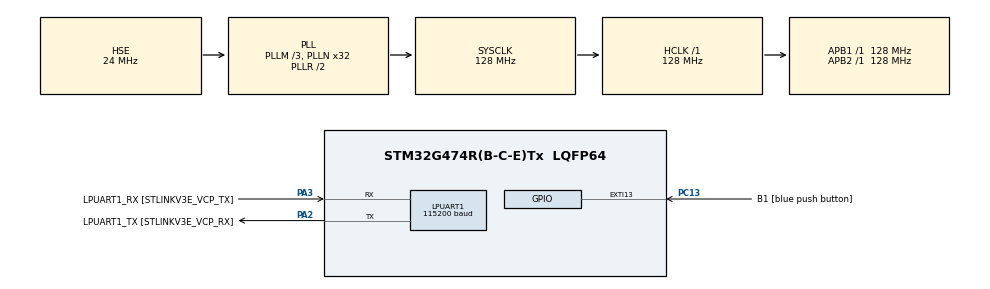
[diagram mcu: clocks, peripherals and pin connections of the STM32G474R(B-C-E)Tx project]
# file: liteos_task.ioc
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LPUART1.BaudRate=115200
LPUART1.WordLength=UART_WORDLENGTH_8B
Mcu.Family=STM32G4
Mcu.Name=STM32G474R(B-C-E)Tx
Mcu.Package=LQFP64
NVIC.EXTI15_10_IRQn=true\:0\:0\:false\:false\:true\:true\:true
NVIC.PriorityGroup=NVIC_PRIORITYGROUP_4
NVIC.TIM4_IRQn=true\:15\:0\:false\:false\:true\:false\:true
NVIC.TimeBase=TIM4_IRQn
NVIC.TimeBaseIP=TIM4
PA13.GPIO_Label=T_SWDIO
PA13.Mode=Serial_Wire
PA13.Signal=SYS_JTMS-SWDIO
PA14.GPIO_Label=T_SWCLK
PA14.Mode=Serial_Wire
PA14.Signal=SYS_JTCK-SWCLK
PA2.GPIO_Label=LPUART1_TX [STLINKV3E_VCP_RX]
PA2.Mode=Asynchronous
PA2.Signal=LPUART1_TX
PA3.GPIO_Label=LPUART1_RX [STLINKV3E_VCP_TX]
PA3.Mode=Asynchronous
PA3.Signal=LPUART1_RX
PA5.GPIO_Label=M_SPI1_SCK
PA5.GPIO_PuPd=GPIO_PULLUP
PA5.GPIO_Speed=GPIO_SPEED_FREQ_HIGH
PA5.Signal=SPI1_SCK
PB3.GPIO_Label=T_SWO
PB3.Signal=SYS_JTDO-SWO
PC13.GPIO_Label=B1 [blue push button]
PC13.Signal=GPXTI13
PC14-OSC32_IN.Signal=RCC_OSC32_IN
PC15-OSC32_OUT.Signal=RCC_OSC32_OUT
PF0-OSC_IN.Mode=HSE-External-Oscillator
PF0-OSC_IN.Signal=RCC_OSC_IN
PF1-OSC_OUT.Mode=HSE-External-Oscillator
PF1-OSC_OUT.Signal=RCC_OSC_OUT
ProjectManager.HeapSize=0x200
ProjectManager.StackSize=0x400
ProjectManager.TargetToolchain=STM32CubeIDE
RCC.ADC12Freq_Value=128000000
RCC.ADC345Freq_Value=128000000
RCC.AHBFreq_Value=128000000
RCC.APB1Freq_Value=128000000
RCC.APB1TimFreq_Value=128000000
RCC.APB2Freq_Value=128000000
RCC.APB2TimFreq_Value=128000000
RCC.CortexFreq_Value=128000000
RCC.EXTERNAL_CLOCK_VALUE=12288000
RCC.HCLKFreq_Value=128000000
RCC.HSE_VALUE=24000000
RCC.HSI48_VALUE=48000000
RCC.HSI_VALUE=16000000
RCC.PLLM=RCC_PLLM_DIV3
RCC.PLLN=32
RCC.PLLSourceVirtual=RCC_PLLSOURCE_HSE
RCC.RTCClockSelection=RCC_RTCCLKSOURCE_LSE
RCC.SYSCLKFreq_VALUE=128000000
RCC.SYSCLKSource=RCC_SYSCLKSOURCE_PLLCLK
RCC.USBFreq_Value=128000000
RCC.VCOOutputFreq_Value=256000000
VP_SYS_VS_DBSignals.Mode=DisableDeadBatterySignals
VP_SYS_VS_tim4.Mode=TIM4
board=NUCLEO-G474RE

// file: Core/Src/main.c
/* USER CODE BEGIN Header */
/**
 ******************************************************************************
 * @file           : main.c
 * @brief          : Main program body
 ******************************************************************************
 * @attention
 *
 * <h2><center>&copy; Copyright (c) 2021 STMicroelectronics.
 * All rights reserved.</center></h2>
 *
 * This software component is licensed by ST under BSD 3-Clause license,
 * the "License"; You may not use this file except in compliance with the
 * License. You may obtain a copy of the License at:
 *                        opensource.org/licenses/BSD-3-Clause
 *
 ******************************************************************************
 */
/* USER CODE END Header */
#include "main.h"
#include "usart.h"
#include "gpio.h"

/* USER CODE BEGIN Includes */
#include "stdio.h"
#include "task1.h"
#include "task2.h"

/* USER CODE END Includes */

/* USER CODE BEGIN PV */

//task1
/**/
UINT32 led1_task_handle;
UINT32 led2_task_handle;
UINT32 print_task_handle;

//task2
/**/
osThreadId_t LED0TaskHandle;
const osThreadAttr_t LED0Task_attributes = {
  .name = "led0task",
  .priority = (osPriority_t) osPriorityNormal,
  .stack_size = 128 * 4
};

osThreadId_t LED1TaskHandle;
const osThreadAttr_t LED1Task_attributes = {
  .name = "led1task",
  .priority = (osPriority_t) osPriorityNormal,
  .stack_size = 128 * 4
};

/* USER CODE END PV */

void SystemClock_Config(void);

int main(void)
{

  /* MCU Configuration--------------------------------------------------------*/

  /* Reset of all peripherals, Initializes the Flash interface and the Systick. */
  HAL_Init();

  /* Configure the system clock */
  SystemClock_Config();

  /* Initialize all configured peripherals */
  MX_GPIO_Init();
  MX_LPUART1_UART_Init();
  /* USER CODE BEGIN 2 */
  //task1
  /*
  TSK_INIT_PARAM_S task_param;
  LOS_KernelInit();

  task_param.pcName = "led1_task";
  task_param.pfnTaskEntry = led1_task;
  task_param.uwStackSize = 1024;
  task_param.usTaskPrio = 4;
  if(LOS_TaskCreate(&led1_task_handle, &task_param) != LOS_OK){
	  PRINT_ERR("create led1 task failed!\r\n");
  }

  task_param.pcName = "led2_task";
  task_param.pfnTaskEntry = led2_task;
  task_param.uwStackSize = 1024;
  task_param.usTaskPrio = 4;
  if(LOS_TaskCreate(&led2_task_handle, &task_param) != LOS_OK){
	  PRINT_ERR("create led2 task failed!\r\n");
  }

  task_param.pcName = "print_task";
  task_param.pfnTaskEntry = print_task;
  task_param.uwStackSize = 1024;
  task_param.usTaskPrio = 4;
  if(LOS_TaskCreate(&print_task_handle, &task_param) != LOS_OK){
	  PRINT_ERR("create print task failed!\r\n");
  }

  LOS_Start();*/

  //task2
  /**/
  // 初始化内核
  osKernelInitialize();
  // 创建LED0任务
  LED0TaskHandle = osThreadNew(LED0TaskEntry, NULL, &LED0Task_attributes);
  // 创建LED1任务
  LED1TaskHandle = osThreadNew(LED1TaskEntry, NULL, &LED1Task_attributes);
  // 启动内核调度
  osKernelStart();

  /* USER CODE END 2 */

  /* Infinite loop */
  while (1) {

  }
}

void SystemClock_Config(void)
{
  RCC_OscInitTypeDef RCC_OscInitStruct = {0};
  RCC_ClkInitTypeDef RCC_ClkInitStruct = {0};
  RCC_PeriphCLKInitTypeDef PeriphClkInit = {0};

  /** Configure the main internal regulator output voltage
  */
  HAL_PWREx_ControlVoltageScaling(PWR_REGULATOR_VOLTAGE_SCALE1);
  /** Initializes the RCC Oscillators according to the specified parameters
  * in the RCC_OscInitTypeDef structure.
  */
  RCC_OscInitStruct.OscillatorType = RCC_OSCILLATORTYPE_HSE;
  RCC_OscInitStruct.HSEState = RCC_HSE_ON;
  RCC_OscInitStruct.PLL.PLLState = RCC_PLL_ON;
  RCC_OscInitStruct.PLL.PLLSource = RCC_PLLSOURCE_HSE;
  RCC_OscInitStruct.PLL.PLLM = RCC_PLLM_DIV3;
  RCC_OscInitStruct.PLL.PLLN = 32;
  RCC_OscInitStruct.PLL.PLLP = RCC_PLLP_DIV2;
  RCC_OscInitStruct.PLL.PLLQ = RCC_PLLQ_DIV2;
  RCC_OscInitStruct.PLL.PLLR = RCC_PLLR_DIV2;
  if (HAL_RCC_OscConfig(&RCC_OscInitStruct) != HAL_OK)
  {
    Error_Handler();
  }
  /** Initializes the CPU, AHB and APB buses clocks
  */
  RCC_ClkInitStruct.ClockType = RCC_CLOCKTYPE_HCLK|RCC_CLOCKTYPE_SYSCLK
                              |RCC_CLOCKTYPE_PCLK1|RCC_CLOCKTYPE_PCLK2;
  RCC_ClkInitStruct.SYSCLKSource = RCC_SYSCLKSOURCE_PLLCLK;
  RCC_ClkInitStruct.AHBCLKDivider = RCC_SYSCLK_DIV1;
  RCC_ClkInitStruct.APB1CLKDivider = RCC_HCLK_DIV1;
  RCC_ClkInitStruct.APB2CLKDivider = RCC_HCLK_DIV1;

  if (HAL_RCC_ClockConfig(&RCC_ClkInitStruct, FLASH_LATENCY_3) != HAL_OK)
  {
    Error_Handler();
  }
  /** Initializes the peripherals clocks
  */
  PeriphClkInit.PeriphClockSelection = RCC_PERIPHCLK_LPUART1;
  PeriphClkInit.Lpuart1ClockSelection = RCC_LPUART1CLKSOURCE_PCLK1;
  if (HAL_RCCEx_PeriphCLKConfig(&PeriphClkInit) != HAL_OK)
  {
    Error_Handler();
  }
}

void HAL_TIM_PeriodElapsedCallback(TIM_HandleTypeDef *htim)
{
  if (htim->Instance == TIM4) {
    HAL_IncTick();
  }
}

void Error_Handler(void)
{
	__disable_irq();
	while (1) {
	}
}

/************************ (C) COPYRIGHT STMicroelectronics *****END OF FILE****/
